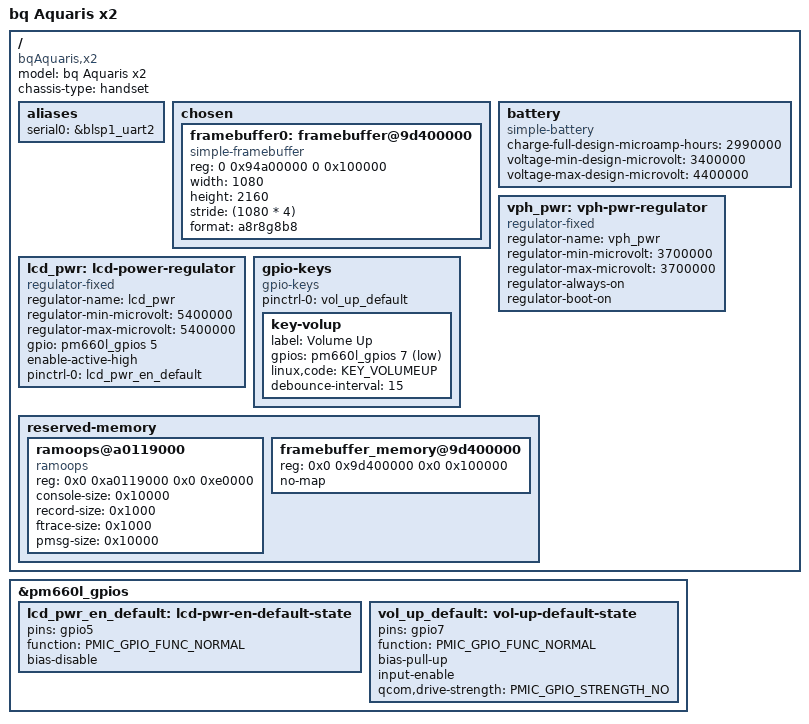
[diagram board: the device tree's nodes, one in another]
// SPDX-License-Identifier: GPL-2.0-only
/*
* Copyright (c) 2025, XiKoTaSu <3329989998@qq.com>
*/

/dts-v1/;

#include "sdm660.dtsi"
#include "pm660.dtsi"
#include "pm660l.dtsi"
#include <dt-bindings/input/input.h>
#include <dt-bindings/input/gpio-keys.h>
#include <dt-bindings/pinctrl/qcom,pmic-gpio.h>

/ {
	model = "bq Aquaris x2";
	compatible = "bqAquaris,x2", "qcom,sdm636";
	chassis-type = "handset";
	
	aliases {
		serial0 = &blsp1_uart2;
	};

	chosen {
		#address-cells = <2>;
		#size-cells = <2>;
		ranges;

		/* stdout-path = "serial0:115200n8"; */

		framebuffer0: framebuffer@9d400000 {
			compatible = "simple-framebuffer";
			reg = <0 0x94a00000 0 0x100000>;
			width = <1080>;
			height = <2160>;
			stride = <(1080 * 4)>;
			format = "a8r8g8b8";
		};
	};
	
	battery: battery {
		compatible = "simple-battery";

		charge-full-design-microamp-hours = <2990000>;
		voltage-min-design-microvolt = <3400000>;
		voltage-max-design-microvolt = <4400000>;
	};

	vph_pwr: vph-pwr-regulator {
		compatible = "regulator-fixed";
		regulator-name = "vph_pwr";
		regulator-min-microvolt = <3700000>;
		regulator-max-microvolt = <3700000>;

		regulator-always-on;
		regulator-boot-on;
	};
	
	lcd_pwr: lcd-power-regulator {
		compatible = "regulator-fixed";
		regulator-name = "lcd_pwr";
		regulator-min-microvolt = <5400000>;
		regulator-max-microvolt = <5400000>;
		gpio = <&pm660l_gpios 5 GPIO_ACTIVE_HIGH>;
		enable-active-high;
		pinctrl-0 = <&lcd_pwr_en_default>;
		pinctrl-names = "default";
	};

	gpio-keys {
		compatible = "gpio-keys";

		pinctrl-names = "default";
		pinctrl-0 = <&vol_up_default>;

		key-volup {
			label = "Volume Up";
			gpios = <&pm660l_gpios 7 GPIO_ACTIVE_LOW>;
			linux,code = <KEY_VOLUMEUP>;
			debounce-interval = <15>;
		};
	};

	reserved-memory {
		#address-cells = <2>;
		#size-cells = <2>;
		ranges;

		ramoops@a0119000 {
			compatible = "ramoops";
			reg = <0x0 0xa0119000 0x0 0xe0000>;
			console-size = <0x10000>;
			record-size = <0x1000>;
			ftrace-size = <0x1000>;
			pmsg-size = <0x10000>;
		};

		framebuffer_memory@9d400000 {
			reg = <0x0 0x9d400000 0x0 0x100000>;
			no-map;
		};
		
	};
};

&pm660l_gpios {
    lcd_pwr_en_default: lcd-pwr-en-default-state {
		pins = "gpio5";
		function = PMIC_GPIO_FUNC_NORMAL;
		bias-disable;
	};
	
	vol_up_default: vol-up-default-state {
		pins = "gpio7";
		function = PMIC_GPIO_FUNC_NORMAL;
		bias-pull-up;
		input-enable;
		qcom,drive-strength = <PMIC_GPIO_STRENGTH_NO>;
	};
};
